# S6E2D3 register map
File version: 1.1
CPU: CM4 r0p1, little endian, MPU, FPU, 4 interrupt priority bits
Registers are 32-bit, read-write, reset 0x0 unless marked. A register's access mark holds for its fields unless they carry their own. Offsets are from the block's base; [hi:lo] are bit positions; {n}, {i} and the like mark numbered series.

## CRG — Clock Unit Registers
Base 0x40010000
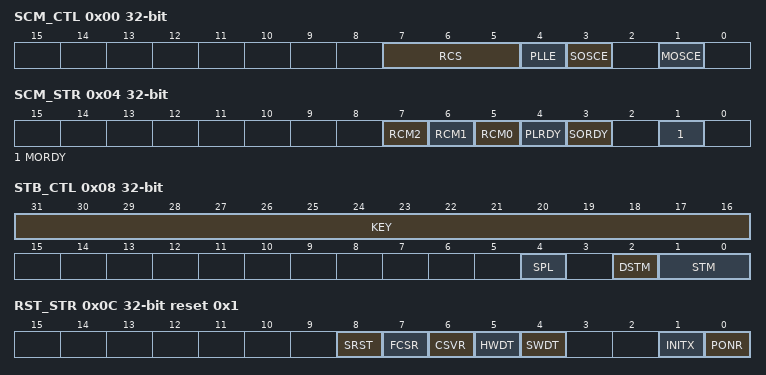
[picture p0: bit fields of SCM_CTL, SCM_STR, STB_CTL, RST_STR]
0x00 SCM_CTL — System Clock Mode Control Register
  [7:5] RCS — Master clock switch control bits
  [4] PLLE — PLL oscillation enable bit
  [3] SOSCE — Sub clock oscillation enable bit
  [1] MOSCE — Main clock oscillation enable bit
0x04 SCM_STR ro — System Clock Mode Status Register
  [7] RCM2 — Master clock selection bit 2
  [6] RCM1 — Master clock selection bit 1
  [5] RCM0 — Master clock selection bit 0
  [4] PLRDY — PLL oscillation stable bit
  [3] SORDY — Sub clock oscillation stable bit
  [1] MORDY — Main clock oscillation stable bit
0x08 STB_CTL — Standby Mode Control Register
  [31:16] KEY — Standby mode control write control bit
  [4] SPL — Standby pin level setting bit
  [2] DSTM — Deep standby mode select bit
  [1:0] STM — Standby mode selection bit
0x0C RST_STR ro reset 0x1 — Reset Cause Register
  [8] SRST — Software reset flag
  [7] FCSR — Flag for anomalous frequency detection reset
  [6] CSVR — Clock failure detection reset flag
  [5] HWDT — Hardware watchdog reset flag
  [4] SWDT — Software watchdog reset flag
  [1] INITX — INITX pin input reset flag
  [0] PONR — Power-on reset/low-voltage detection reset flag
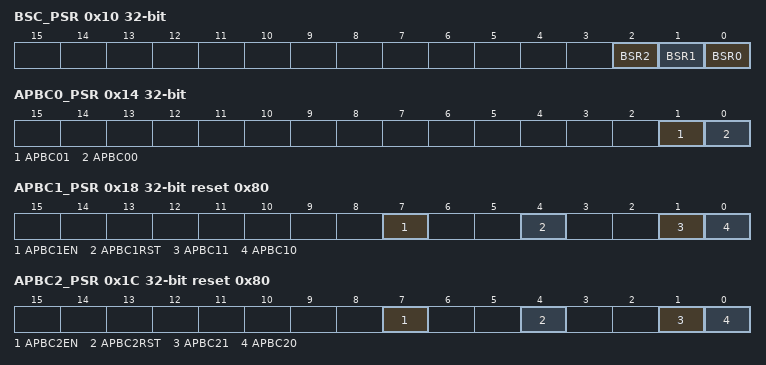
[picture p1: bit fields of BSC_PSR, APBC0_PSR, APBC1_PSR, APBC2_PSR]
0x10 BSC_PSR — Base Clock Prescaler Register
  [2] BSR2 — Base clock frequency division ratio setting bit
  [1] BSR1 — Base clock frequency division ratio setting bit
  [0] BSR0 — Base clock frequency division ratio setting bit
0x14 APBC0_PSR — APB0 Prescaler Register
  [1] APBC01 — APB0 bus clock frequency division ratio setting bit 1
  [0] APBC00 — APB0 bus clock frequency division ratio setting bit 0
0x18 APBC1_PSR reset 0x80 — APB1 Prescaler Register
  [7] APBC1EN — APB1 clock enable bit
  [4] APBC1RST — APB1 bus reset control bit
  [1] APBC11 — APB1 bus clock frequency division ratio setting bit 1
  [0] APBC10 — APB1 bus clock frequency division ratio setting bit 0
0x1C APBC2_PSR reset 0x80 — APB2 Prescaler Register
  [7] APBC2EN — APB2 clock enable bit
  [4] APBC2RST — APB2 bus reset control bit
  [1] APBC21 — APB2 bus clock frequency division ratio setting bit 1
  [0] APBC20 — APB2 bus clock frequency division ratio setting bit 0
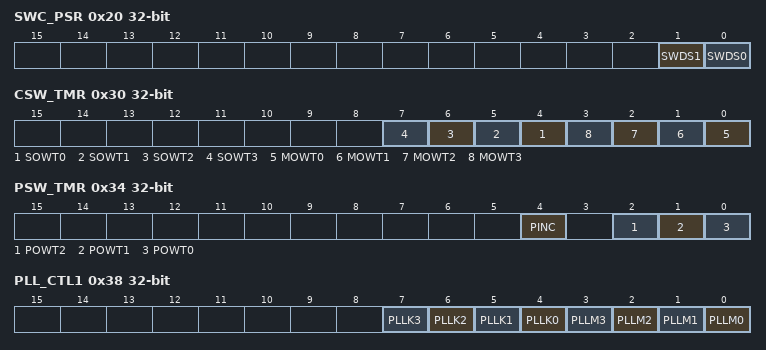
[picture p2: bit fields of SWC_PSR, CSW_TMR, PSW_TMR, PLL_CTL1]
0x20 SWC_PSR — Software Watchdog Clock Prescaler Register
  [1] SWDS1 — Software watchdog clock frequency division ratio setting bit 1
  [0] SWDS0 — Software watchdog clock frequency division ratio setting bit 0
0x28 TTC_PSR — Trace Clock Prescaler Register
  [1:0] TTC — Trace clock frequency division ratio setting bit
0x30 CSW_TMR — Clock Stabilization Wait Time Register
  [n+4] SOWT{n} (n=0..3) — Sub clock stabilization wait time setup bit {n}
  [n] MOWT{n} (n=0..3) — Main clock stabilization wait time setup bit {n}
0x34 PSW_TMR — PLL Clock Stabilization Wait Time Setup Register
  [4] PINC — PLL input clock select bit
  [2] POWT2 — PLL clock stabilization wait time setup bit 2
  [1] POWT1 — PLL clock stabilization wait time setup bit 1
  [0] POWT0 — PLL clock stabilization wait time setup bit 0
0x38 PLL_CTL1 — PLL Control Register 1
  [n+4] PLLK{n} (n=0..3) — PLL input clock frequency division ratio setting bit {n}
  [n] PLLM{n} (n=0..3) — PLL VCO clock frequency division ratio setting bit {n}
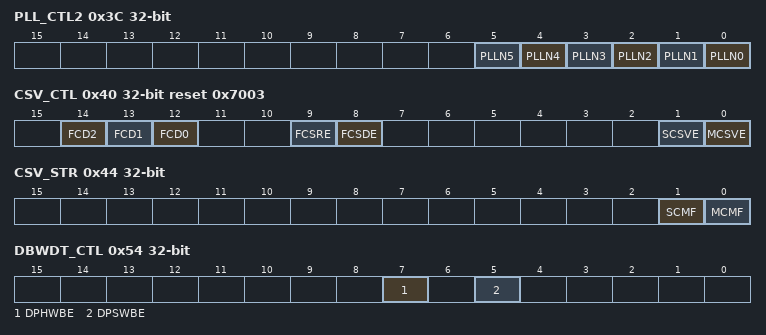
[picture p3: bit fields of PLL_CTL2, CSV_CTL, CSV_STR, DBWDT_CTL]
0x3C PLL_CTL2 — PLL Control Register 2
  [n] PLLN{n} (n=0..5) — PLL feedback frequency division ratio setting bit {n}
0x40 CSV_CTL reset 0x7003 — CSV control register
  [14] FCD2 — FCS count cycle setting bit 2
  [13] FCD1 — FCS count cycle setting bit 1
  [12] FCD0 — FCS count cycle setting bit 0
  [9] FCSRE — FCS reset output enable bit
  [8] FCSDE — FCS function enable bit
  [1] SCSVE — Sub CSV function enable bit
  [0] MCSVE — Main CSV function enable bit
0x44 CSV_STR ro — CSV status register
  [1] SCMF — Sub clock failure detection flag
  [0] MCMF — Main clock failure detection flag
0x48 FCSWH_CTL reset 0xFFFF — Frequency detection window setting register
  [15:0] FWH — Frequency detection window setting bits (Upper)
0x4C FCSWL_CTL — Frequency detection window setting register
  [15:0] FWL — Frequency detection window setting bits (Lower)
0x50 FCSWD_CTL ro — Frequency detection counter register
  [15:0] FWD — Frequency detection count data
0x54 DBWDT_CTL — Debug Break Watchdog Timer Control Register
  [7] DPHWBE — HW-WDG debug mode break bit
  [5] DPSWBE — SW-WDG debug mode break bit
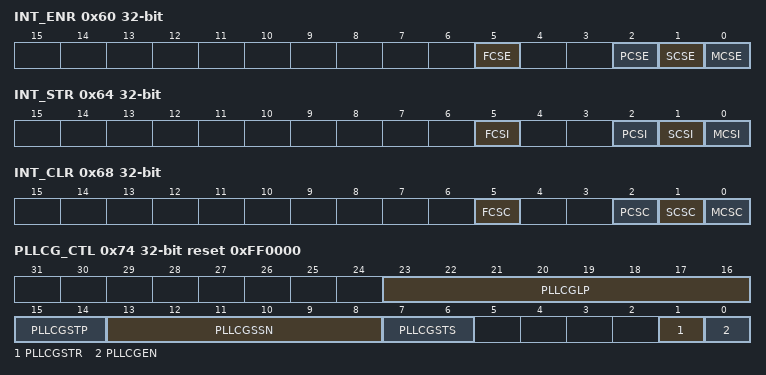
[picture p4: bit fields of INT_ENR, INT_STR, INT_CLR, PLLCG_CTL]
0x60 INT_ENR — Interrupt Enable Register
  [5] FCSE — Anomalous frequency detection interrupt enable bit
  [2] PCSE — PLL oscillation stabilization completion interrupt enable bit
  [1] SCSE — Sub oscillation stabilization completion interrupt enable bit
  [0] MCSE — Main oscillation stabilization completion interrupt enable bit
0x64 INT_STR ro — Interrupt Status Register
  [5] FCSI — Anomalous frequency detection interrupt status bit
  [2] PCSI — PLL oscillation stabilization completion interrupt status bit
  [1] SCSI — Sub oscillation stabilization completion interrupt status bit
  [0] MCSI — Main oscillation stabilization completion interrupt status bit
0x68 INT_CLR wo — Interrupt Clear Register
  [5] FCSC — Anomalous frequency detection interrupt cause clear bit
  [2] PCSC — PLL oscillation stabilization completion interrupt cause clear bit
  [1] SCSC — Sub oscillation stabilization completion interrupt cause clear bit
  [0] MCSC — Main oscillation stabilization completion interrupt cause clear bit
0x74 PLLCG_CTL reset 0xFF0000 — PLL Clock Gear Control Register
  [23:16] PLLCGLP — PLL clock gear step loop configuration bits
  [15:14] PLLCGSTP — PLL clock gear step configuration bits
  [13:8] PLLCGSSN — PLL clock gear start step number configuration bits
  [7:6] PLLCGSTS — PLL clock gear start bits
  [1] PLLCGSTR — PLL clock gear start bit
  [0] PLLCGEN — PLL clock gear enable bit

## Notices in the file
Copyright (C) 2015 Spansion LLC. All Rights Reserved.
This software is owned and published by:
Spansion LLC, 915 DeGuigne Dr. Sunnyvale, CA  94088-3453 ("Spansion").
BY DOWNLOADING, INSTALLING OR USING THIS SOFTWARE, YOU AGREE TO BE BOUND
BY ALL THE TERMS AND CONDITIONS OF THIS AGREEMENT.
This software contains source code for use with Spansion
components. This software is licensed by Spansion to be adapted only
for use in systems utilizing Spansion components. Spansion shall not be
responsible for misuse or illegal use of this software for devices not
supported herein.  Spansion is providing this software "AS IS" and will
not be responsible for issues arising from incorrect user implementation
of the software.
SPANSION MAKES NO WARRANTY, EXPRESS OR IMPLIED, ARISING BY LAW OR OTHERWISE,
REGARDING THE SOFTWARE (INCLUDING ANY ACOOMPANYING WRITTEN MATERIALS),
ITS PERFORMANCE OR SUITABILITY FOR YOUR INTENDED USE, INCLUDING,
WITHOUT LIMITATION, THE IMPLIED WARRANTY OF MERCHANTABILITY, THE IMPLIED
WARRANTY OF FITNESS FOR A PARTICULAR PURPOSE OR USE, AND THE IMPLIED
WARRANTY OF NONINFRINGEMENT.
SPANSION SHALL HAVE NO LIABILITY (WHETHER IN CONTRACT, WARRANTY, TORT,
NEGLIGENCE OR OTHERWISE) FOR ANY DAMAGES WHATSOEVER (INCLUDING, WITHOUT
LIMITATION, DAMAGES FOR LOSS OF BUSINESS PROFITS, BUSINESS INTERRUPTION,
LOSS OF BUSINESS INFORMATION, OR OTHER PECUNIARY LOSS) ARISING FROM USE OR
INABILITY TO USE THE SOFTWARE, INCLUDING, WITHOUT LIMITATION, ANY DIRECT,
INDIRECT, INCIDENTAL, SPECIAL OR CONSEQUENTIAL DAMAGES OR LOSS OF DATA,
SAVINGS OR PROFITS,
EVEN IF SPANSION HAS BEEN ADVISED OF THE POSSIBILITY OF SUCH DAMAGES.
YOU ASSUME ALL RESPONSIBILITIES FOR SELECTION OF THE SOFTWARE TO ACHIEVE YOUR
INTENDED RESULTS, AND FOR THE INSTALLATION OF, USE OF, AND RESULTS OBTAINED
FROM, THE SOFTWARE.
This software may be replicated in part or whole for the licensed use,
with the restriction that this Disclaimer and Copyright notice must be
included with each copy of this software, whether used in part or whole,
at all times.
